# STM32L152xD register map
File version: 1.0
Registers are 32-bit, read-write, reset 0x0 unless marked. A register's access mark holds for its fields unless they carry their own. Offsets are from the block's base; [hi:lo] are bit positions; {n}, {i} and the like mark numbered series; 'fields as' and 'values as' point back to an identical list.

## DMA1
Base 0x40026000
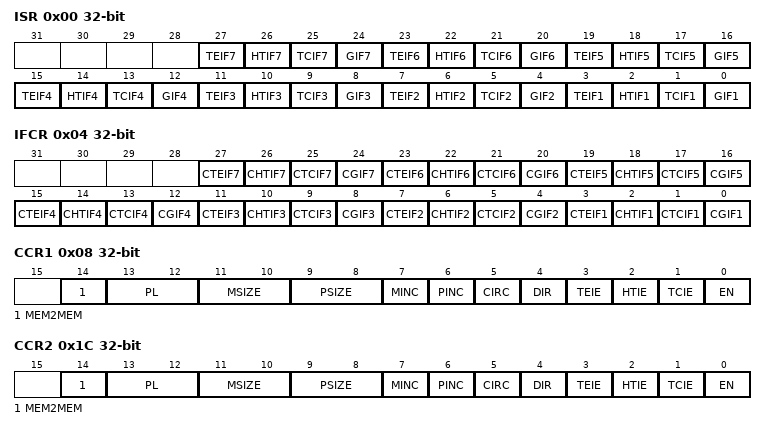
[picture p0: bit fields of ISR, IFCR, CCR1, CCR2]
0x00 ISR — DMA interrupt status register
  [4n-1] TEIF{n} (n=1..7) — Channel {n} Transfer Error flag
  [4n-2] HTIF{n} (n=1..7) — Channel {n} Half Transfer flag
  [4n-3] TCIF{n} (n=1..7) — Channel {n} Transfer Complete flag
  [4n-4] GIF{n} (n=1..7) — Channel {n} Global interrupt flag
0x04 IFCR — DMA interrupt flag clear register
  [4n-1] CTEIF{n} (n=1..7) — Channel {n} Transfer Error clear
  [4n-2] CHTIF{n} (n=1..7) — Channel {n} Half Transfer clear
  [4n-3] CTCIF{n} (n=1..7) — Channel {n} Transfer Complete clear
  [4n-4] CGIF{n} (n=1..7) — Channel {n} Global interrupt clear
0x08 CCR1 — DMA channel x configuration register
  [14] MEM2MEM — Memory to memory mode
  [13:12] PL — PL[1:0] bits(Channel Priority level)
  [11:10] MSIZE — MSIZE[1:0] bits (Memory size)
  [9:8] PSIZE — PSIZE[1:0] bits (Peripheral size)
  [7] MINC — Memory increment mode
  [6] PINC — Peripheral increment mode
  [5] CIRC — Circular mode
  [4] DIR — Data transfer direction
  [3] TEIE — Transfer error interrupt enable
  [2] HTIE — Half Transfer interrupt enable
  [1] TCIE — Transfer complete interrupt enable
  [0] EN — Channel enable
0x0C CNDTR1 — DMA channel x number of data register
  [15:0] NDT — Number of data to Transfer
0x10 CPAR1 — DMA channel x peripheral address register
  [31:0] PA — Peripheral Address
{0x0+0x14*i} CMAR{i} (i=1..7) — DMA channel x memory address register
  [31:0] MA — Memory Address
0x1C CCR2 — DMA channel x configuration register
  fields as CCR1
0x20 CNDTR2 — DMA channel x number of data register
  [15:0] NDT — Number of data to Transfer
0x24 CPAR2 — DMA channel x peripheral address register
  [31:0] PA — Peripheral Address
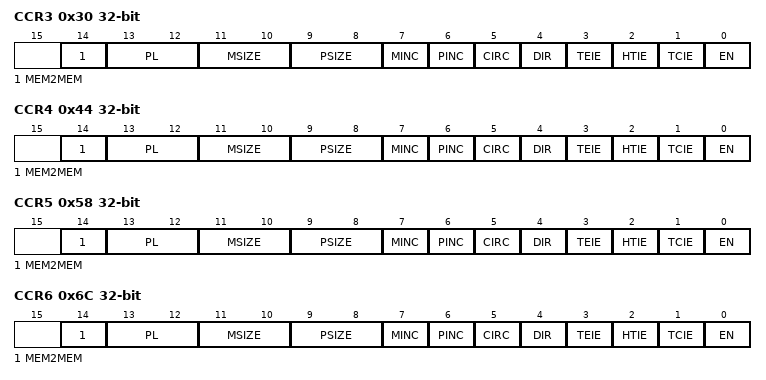
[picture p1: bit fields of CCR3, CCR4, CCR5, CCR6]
0x30 CCR3 — DMA channel x configuration register
  fields as CCR1
0x34 CNDTR3 — DMA channel x number of data register
  [15:0] NDT — Number of data to Transfer
0x38 CPAR3 — DMA channel x peripheral address register
  [31:0] PA — Peripheral Address
0x44 CCR4 — DMA channel x configuration register
  fields as CCR1
0x48 CNDTR4 — DMA channel x number of data register
  [15:0] NDT — Number of data to Transfer
0x4C CPAR4 — DMA channel x peripheral address register
  [31:0] PA — Peripheral Address
0x58 CCR5 — DMA channel x configuration register
  fields as CCR1
0x5C CNDTR5 — DMA channel x number of data register
  [15:0] NDT — Number of data to Transfer
0x60 CPAR5 — DMA channel x peripheral address register
  [31:0] PA — Peripheral Address
0x6C CCR6 — DMA channel x configuration register
  fields as CCR1
0x70 CNDTR6 — DMA channel x number of data register
  [15:0] NDT — Number of data to Transfer
0x74 CPAR6 — DMA channel x peripheral address register
  [31:0] PA — Peripheral Address
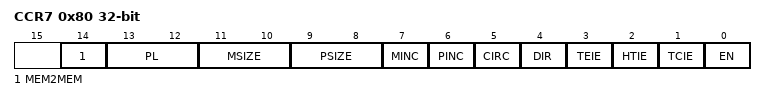
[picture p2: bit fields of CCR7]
0x80 CCR7 — DMA channel x configuration register
  fields as CCR1
0x84 CNDTR7 — DMA channel x number of data register
  [15:0] NDT — Number of data to Transfer
0x88 CPAR7 — DMA channel x peripheral address register
  [31:0] PA — Peripheral Address

## DMA2
Base 0x40026400
Registers as DMA1, without CCR6, CNDTR6, CPAR6, CMAR6, CCR7, CNDTR7, CPAR7, CMAR7.

## FSMC_Bank1 — Flexible Static Memory Controller
Base 0xA0000000
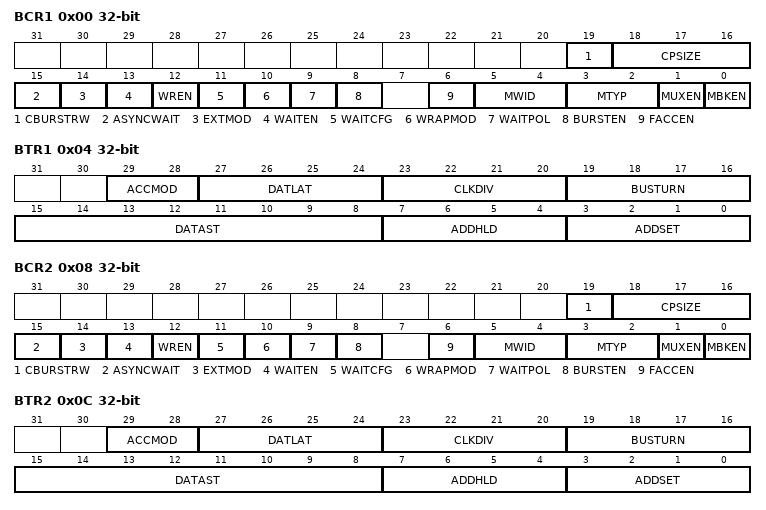
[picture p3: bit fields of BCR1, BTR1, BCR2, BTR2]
0x00 BCR1 — NOR/PSRAM chip-select control register(BCR) and chip-select timing register(BTR)
  [19] CBURSTRW — Write burst enable
  [18:16] CPSIZE — Cellular RAM page size
  [15] ASYNCWAIT — Asynchronous wait
  [14] EXTMOD — Extended mode enable
  [13] WAITEN — Wait enable bit
  [12] WREN — Write enable bit
  [11] WAITCFG — Wait timing configuration
  [10] WRAPMOD — Wrapped burst mode support
  [9] WAITPOL — Wait signal polarity bit
  [8] BURSTEN — Burst enable bit
  [6] FACCEN — Flash access enable
  [5:4] MWID — MWID[1:0] bits (Memory data bus width)
  [3:2] MTYP — MTYP[1:0] bits (Memory type)
  [1] MUXEN — Address/data multiplexing enable bit
  [0] MBKEN — Memory bank enable bit
0x04 BTR1 — NOR/PSRAM chip-select control register(BCR) and chip-select timing register(BTR)
  [29:28] ACCMOD — ACCMOD[1:0] bits (Access mode)
  [27:24] DATLAT — DATLA[3:0] bits (Data latency)
  [23:20] CLKDIV — CLKDIV[3:0] bits (Clock divide ratio)
  [19:16] BUSTURN — BUSTURN[3:0] bits (Bus turnaround phase duration)
  [15:8] DATAST — DATAST [7:0] bits (Data-phase duration)
  [7:4] ADDHLD — ADDHLD[3:0] bits (Address-hold phase duration)
  [3:0] ADDSET — ADDSET[3:0] bits (Address setup phase duration)
0x08 BCR2 — NOR/PSRAM chip-select control register(BCR) and chip-select timing register(BTR)
  fields as BCR1
0x0C BTR2 — NOR/PSRAM chip-select control register(BCR) and chip-select timing register(BTR)
  fields as BTR1
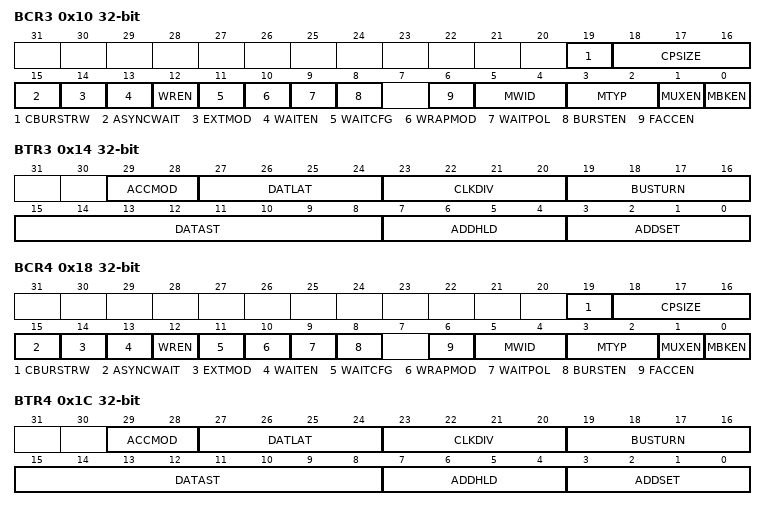
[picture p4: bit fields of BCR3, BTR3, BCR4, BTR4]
0x10 BCR3 — NOR/PSRAM chip-select control register(BCR) and chip-select timing register(BTR)
  fields as BCR1
0x14 BTR3 — NOR/PSRAM chip-select control register(BCR) and chip-select timing register(BTR)
  fields as BTR1
0x18 BCR4 — NOR/PSRAM chip-select control register(BCR) and chip-select timing register(BTR)
  fields as BCR1
0x1C BTR4 — NOR/PSRAM chip-select control register(BCR) and chip-select timing register(BTR)
  fields as BTR1

## FSMC_Bank1E — Flexible Static Memory Controller Bank1E
Base 0xA0000104
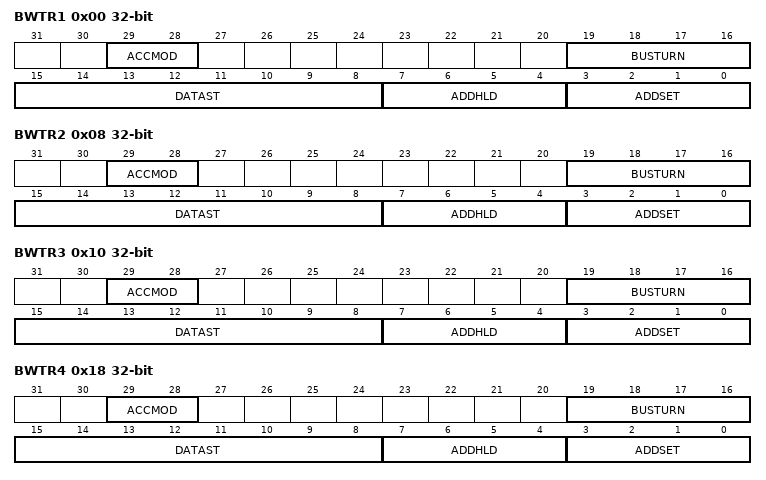
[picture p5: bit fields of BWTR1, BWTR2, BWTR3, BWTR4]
0x00 BWTR1 — NOR/PSRAM write timing registers
  [29:28] ACCMOD — ACCMOD[1:0] bits (Access mode)
  [19:16] BUSTURN — BUSTURN[3:0] bits (Bus turnaround phase duration)
  [15:8] DATAST — DATAST [7:0] bits (Data-phase duration)
  [7:4] ADDHLD — ADDHLD[3:0] bits (Address-hold phase duration)
  [3:0] ADDSET — ADDSET[3:0] bits (Address setup phase duration)
0x08 BWTR2 — NOR/PSRAM write timing registers
  fields as BWTR1
0x10 BWTR3 — NOR/PSRAM write timing registers
  fields as BWTR1
0x18 BWTR4 — NOR/PSRAM write timing registers
  fields as BWTR1

## DBGMCU — Debug MCU
Base 0xE0042000
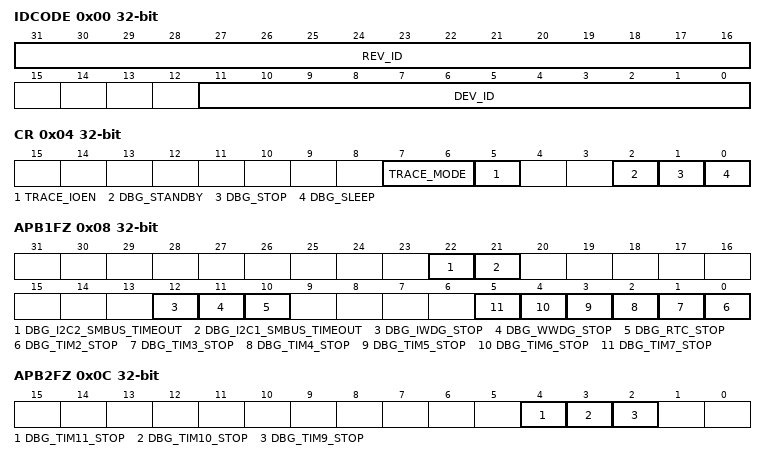
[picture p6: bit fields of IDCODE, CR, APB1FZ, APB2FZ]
0x00 IDCODE — MCU device ID code
  [31:16] REV_ID — REV_ID[15:0] bits (Revision Identifier)
  [11:0] DEV_ID — Device Identifier
0x04 CR — Debug MCU configuration register
  [7:6] TRACE_MODE — TRACE_MODE[1:0] bits (Trace Pin Assignment Control)
  [5] TRACE_IOEN — Trace Pin Assignment Control
  [2] DBG_STANDBY — Debug Standby mode
  [1] DBG_STOP — Debug Stop Mode
  [0] DBG_SLEEP — Debug Sleep Mode
0x08 APB1FZ — Debug MCU APB1 freeze register
  [22] DBG_I2C2_SMBUS_TIMEOUT — SMBUS timeout mode stopped when Core is halted
  [21] DBG_I2C1_SMBUS_TIMEOUT — SMBUS timeout mode stopped when Core is halted
  [12] DBG_IWDG_STOP — Debug Independent Watchdog stopped when Core is halted
  [11] DBG_WWDG_STOP — Debug Window Watchdog stopped when Core is halted
  [10] DBG_RTC_STOP — RTC Counter stopped when Core is halted
  [n-2] DBG_TIM{n}_STOP (n=2..7) — TIM{n} counter stopped when core is halted
0x0C APB2FZ — Debug MCU APB2 freeze register
  [4] DBG_TIM11_STOP — TIM11 counter stopped when core is halted
  [3] DBG_TIM10_STOP — TIM10 counter stopped when core is halted
  [2] DBG_TIM9_STOP — TIM9 counter stopped when core is halted
